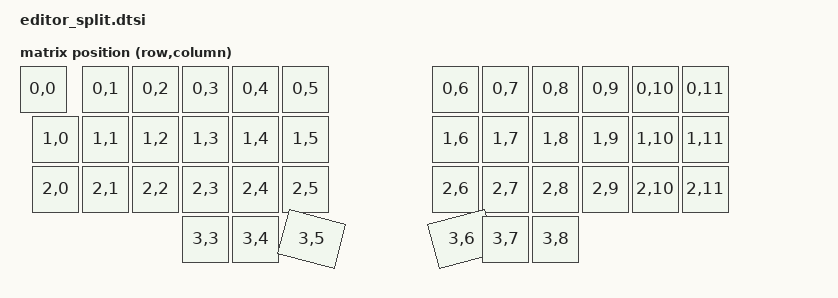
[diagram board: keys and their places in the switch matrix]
/* Generated by ZMK Editor from editor_split.editor.json. */

#include <dt-bindings/zmk/matrix_transform.h>
#include <physical_layouts.dtsi>

/ {
    chosen {
        zmk,kscan = &kscan0;
        zmk,physical-layout = &editor_split_layout;
    };

    kscan0: kscan {
        compatible = "zmk,kscan-gpio-matrix";
        wakeup-source;
        diode-direction = "col2row";
    };

    default_transform: keymap_transform_0 {
        compatible = "zmk,matrix-transform";
        rows = <4>;
        columns = <12>;
        map = <
RC(0,0)  RC(0,1)  RC(0,2)  RC(0,3)  RC(0,4)  RC(0,5)  RC(0,6)  RC(0,7)  RC(0,8)  RC(0,9)  RC(0,10) RC(0,11)
RC(1,0)  RC(1,1)  RC(1,2)  RC(1,3)  RC(1,4)  RC(1,5)  RC(1,6)  RC(1,7)  RC(1,8)  RC(1,9)  RC(1,10) RC(1,11)
RC(2,0)  RC(2,1)  RC(2,2)  RC(2,3)  RC(2,4)  RC(2,5)  RC(2,6)  RC(2,7)  RC(2,8)  RC(2,9)  RC(2,10) RC(2,11)
                           RC(3,3)  RC(3,4)  RC(3,5)  RC(3,6)  RC(3,7)  RC(3,8)
        >;
    };

    editor_split_layout: editor_split_layout {
        compatible = "zmk,physical-layout";
        display-name = "Editor Split";
        transform = <&default_transform>;

        keys  //                     w   h    x    y     rot   rx   ry
            = <&key_physical_attrs 100 100    0    0      0    0    0>
            , <&key_physical_attrs 100 100  125    0      0    0    0>
            , <&key_physical_attrs 100 100  225    0      0    0    0>
            , <&key_physical_attrs 100 100  325    0      0    0    0>
            , <&key_physical_attrs 100 100  425    0      0    0    0>
            , <&key_physical_attrs 100 100  525    0      0    0    0>
            , <&key_physical_attrs 100 100  825    0      0    0    0>
            , <&key_physical_attrs 100 100  925    0      0    0    0>
            , <&key_physical_attrs 100 100 1025    0      0    0    0>
            , <&key_physical_attrs 100 100 1125    0      0    0    0>
            , <&key_physical_attrs 100 100 1225    0      0    0    0>
            , <&key_physical_attrs 100 100 1325    0      0    0    0>
            , <&key_physical_attrs 100 100   25  100      0    0    0>
            , <&key_physical_attrs 100 100  125  100      0    0    0>
            , <&key_physical_attrs 100 100  225  100      0    0    0>
            , <&key_physical_attrs 100 100  325  100      0    0    0>
            , <&key_physical_attrs 100 100  425  100      0    0    0>
            , <&key_physical_attrs 100 100  525  100      0    0    0>
            , <&key_physical_attrs 100 100  825  100      0    0    0>
            , <&key_physical_attrs 100 100  925  100      0    0    0>
            , <&key_physical_attrs 100 100 1025  100      0    0    0>
            , <&key_physical_attrs 100 100 1125  100      0    0    0>
            , <&key_physical_attrs 100 100 1225  100      0    0    0>
            , <&key_physical_attrs 100 100 1325  100      0    0    0>
            , <&key_physical_attrs 100 100   25  200      0    0    0>
            , <&key_physical_attrs 100 100  125  200      0    0    0>
            , <&key_physical_attrs 100 100  225  200      0    0    0>
            , <&key_physical_attrs 100 100  325  200      0    0    0>
            , <&key_physical_attrs 100 100  425  200      0    0    0>
            , <&key_physical_attrs 100 100  525  200      0    0    0>
            , <&key_physical_attrs 100 100  825  200      0    0    0>
            , <&key_physical_attrs 100 100  925  200      0    0    0>
            , <&key_physical_attrs 100 100 1025  200      0    0    0>
            , <&key_physical_attrs 100 100 1125  200      0    0    0>
            , <&key_physical_attrs 100 100 1225  200      0    0    0>
            , <&key_physical_attrs 100 100 1325  200      0    0    0>
            , <&key_physical_attrs 100 100  325  300      0    0    0>
            , <&key_physical_attrs 100 100  425  300      0    0    0>
            , <&key_physical_attrs 125 100  525  300   1500  588  350>
            , <&key_physical_attrs 125 100  825  300 (-1500)  888  350>
            , <&key_physical_attrs 100 100  925  300      0    0    0>
            , <&key_physical_attrs 100 100 1025  300      0    0    0>
            ;
    };
};
